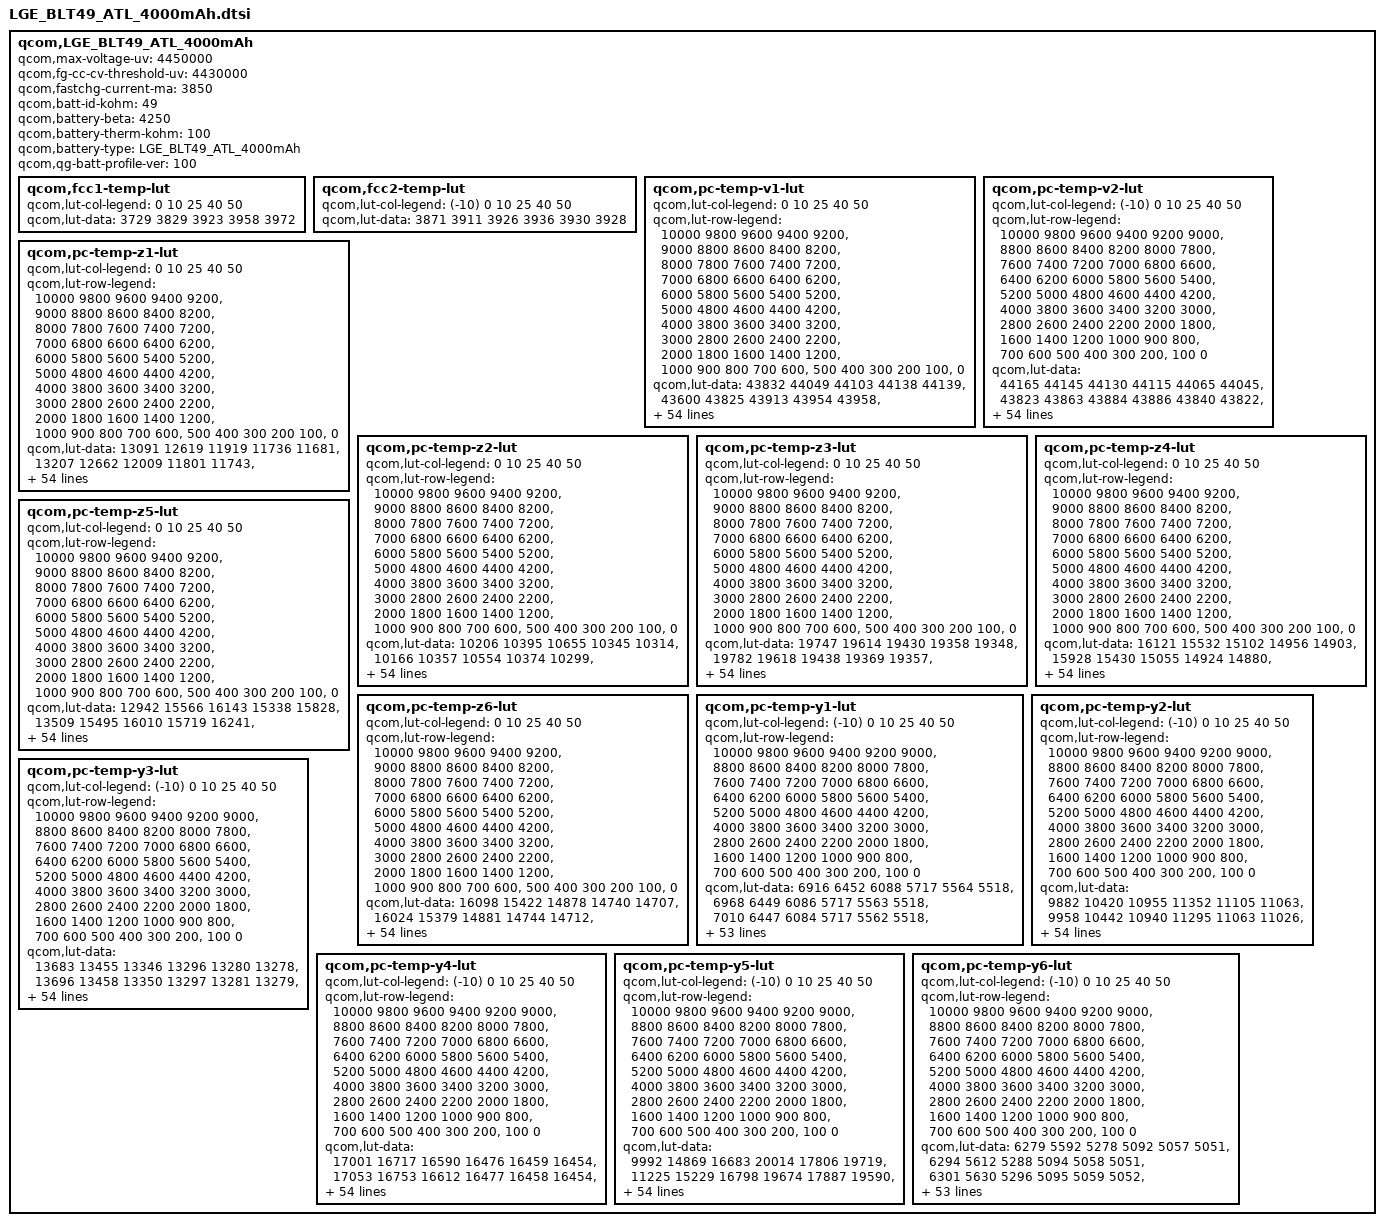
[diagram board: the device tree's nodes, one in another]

qcom,LGE_BLT49_ATL_4000mAh {
    /* 4555251_LGE_BLT49atl_4000mAh_averaged_MasterSlave_May26th2020 */
    qcom,max-voltage-uv = <4450000>;
    qcom,fg-cc-cv-threshold-uv = <4430000>;
    qcom,fastchg-current-ma = <3850>;
    qcom,batt-id-kohm = <49>;
    qcom,battery-beta = <4250>;
    qcom,battery-therm-kohm = <100>;
    qcom,battery-type = "LGE_BLT49_ATL_4000mAh";
    qcom,qg-batt-profile-ver = <100>;

	qcom,fcc1-temp-lut {
		qcom,lut-col-legend = <0 10 25 40 50>;
		qcom,lut-data = <3729 3829 3923 3958 3972>;
	};

	qcom,fcc2-temp-lut {
		qcom,lut-col-legend = <(-10) 0 10 25 40 50>;
		qcom,lut-data = <3871 3911 3926 3936 3930 3928>;
	};

	qcom,pc-temp-v1-lut {
		qcom,lut-col-legend = <0 10 25 40 50>;
		qcom,lut-row-legend = <10000 9800 9600 9400 9200>,
			<9000 8800 8600 8400 8200>,
			<8000 7800 7600 7400 7200>,
			<7000 6800 6600 6400 6200>,
			<6000 5800 5600 5400 5200>,
			<5000 4800 4600 4400 4200>,
			<4000 3800 3600 3400 3200>,
			<3000 2800 2600 2400 2200>,
			<2000 1800 1600 1400 1200>,
			<1000 900 800 700 600>,
			<500 400 300 200 100>,
			<0>;
		qcom,lut-data = <43832 44049 44103 44138 44139>,
			<43600 43825 43913 43954 43958>,
			<43369 43598 43713 43760 43767>,
			<43137 43370 43505 43556 43567>,
			<42905 43139 43287 43343 43357>,
			<42671 42906 43060 43121 43138>,
			<42437 42672 42824 42887 42907>,
			<42205 42433 42585 42648 42671>,
			<41981 42195 42342 42410 42434>,
			<41762 41963 42100 42169 42194>,
			<41546 41735 41864 41933 41957>,
			<41330 41512 41632 41698 41722>,
			<41118 41294 41406 41468 41492>,
			<40917 41083 41186 41242 41265>,
			<40724 40877 40973 41021 41044>,
			<40533 40678 40767 40811 40831>,
			<40338 40486 40567 40609 40626>,
			<40143 40306 40376 40416 40429>,
			<39966 40133 40205 40237 40248>,
			<39818 39955 40031 40065 40076>,
			<39677 39773 39809 39865 39883>,
			<39516 39580 39527 39603 39633>,
			<39333 39353 39287 39351 39383>,
			<39150 39082 39122 39174 39199>,
			<38974 38883 38987 39031 39049>,
			<38803 38785 38867 38901 38914>,
			<38677 38715 38761 38779 38790>,
			<38592 38641 38661 38668 38677>,
			<38525 38565 38563 38568 38573>,
			<38470 38493 38468 38476 38477>,
			<38425 38425 38385 38391 38389>,
			<38385 38360 38310 38312 38306>,
			<38345 38304 38244 38239 38230>,
			<38308 38252 38188 38174 38161>,
			<38271 38206 38139 38115 38098>,
			<38238 38168 38092 38056 38033>,
			<38202 38137 38047 37997 37965>,
			<38155 38098 37999 37934 37891>,
			<38086 38031 37932 37857 37806>,
			<38000 37939 37845 37767 37709>,
			<37897 37836 37746 37667 37603>,
			<37769 37715 37631 37555 37487>,
			<37620 37576 37498 37427 37354>,
			<37456 37409 37335 37262 37189>,
			<37332 37257 37183 37123 37056>,
			<37225 37147 37089 37035 36975>,
			<37187 37115 37064 37011 36953>,
			<37155 37097 37049 36996 36936>,
			<37124 37073 37027 36976 36917>,
			<37073 37034 36989 36932 36863>,
			<36903 36874 36790 36699 36610>,
			<36472 36440 36355 36263 36174>,
			<35897 35860 35790 35696 35606>,
			<35110 35061 35020 34928 34837>,
			<33799 33732 33820 33739 33645>,
			<30000 30000 30000 30000 30000>;
	};

	qcom,pc-temp-v2-lut {
		qcom,lut-col-legend = <(-10) 0 10 25 40 50>;
		qcom,lut-row-legend = <10000 9800 9600 9400 9200 9000>,
			<8800 8600 8400 8200 8000 7800>,
			<7600 7400 7200 7000 6800 6600>,
			<6400 6200 6000 5800 5600 5400>,
			<5200 5000 4800 4600 4400 4200>,
			<4000 3800 3600 3400 3200 3000>,
			<2800 2600 2400 2200 2000 1800>,
			<1600 1400 1200 1000 900 800>,
			<700 600 500 400 300 200>,
			<100 0>;
		qcom,lut-data = <44165 44145 44130 44115 44065 44045>,
			<43823 43863 43884 43886 43840 43822>,
			<43512 43596 43645 43658 43615 43600>,
			<43235 43345 43412 43432 43392 43379>,
			<42993 43113 43189 43210 43171 43160>,
			<42758 42881 42963 42983 42947 42937>,
			<42507 42637 42726 42746 42713 42704>,
			<42250 42390 42483 42504 42473 42466>,
			<41999 42144 42241 42262 42235 42229>,
			<41744 41902 41996 42022 41996 41991>,
			<41507 41661 41756 41784 41760 41757>,
			<41319 41413 41522 41550 41528 41526>,
			<41160 41165 41294 41321 41301 41299>,
			<40963 40961 41075 41097 41079 41077>,
			<40634 40821 40866 40881 40862 40860>,
			<40254 40679 40663 40671 40654 40651>,
			<39965 40456 40468 40467 40453 40451>,
			<39730 40143 40279 40269 40259 40259>,
			<39513 39854 40069 40081 40072 40074>,
			<39303 39619 39810 39910 39901 39903>,
			<39103 39403 39544 39732 39724 39728>,
			<38913 39194 39317 39500 39498 39506>,
			<38724 38995 39111 39216 39223 39235>,
			<38562 38808 38930 38987 38998 39011>,
			<38444 38631 38774 38828 38844 38856>,
			<38350 38469 38636 38697 38716 38728>,
			<38269 38331 38509 38576 38597 38608>,
			<38200 38207 38394 38466 38488 38499>,
			<38138 38109 38287 38366 38390 38399>,
			<38078 38046 38183 38273 38298 38306>,
			<38021 37997 38087 38188 38215 38221>,
			<37964 37951 38002 38110 38140 38143>,
			<37907 37908 37926 38038 38072 38073>,
			<37849 37866 37863 37970 38004 38001>,
			<37789 37822 37821 37906 37927 37917>,
			<37727 37776 37786 37844 37846 37824>,
			<37660 37725 37745 37773 37756 37724>,
			<37590 37666 37699 37690 37652 37608>,
			<37514 37598 37643 37604 37549 37497>,
			<37433 37516 37568 37520 37458 37406>,
			<37341 37417 37470 37435 37371 37324>,
			<37246 37304 37356 37334 37271 37226>,
			<37156 37163 37212 37210 37147 37097>,
			<37070 37018 37059 37078 37023 36968>,
			<36990 36882 36897 36942 36900 36847>,
			<36907 36791 36810 36890 36858 36807>,
			<36858 36759 36784 36874 36847 36796>,
			<36804 36727 36759 36859 36834 36784>,
			<36744 36693 36717 36836 36810 36760>,
			<36676 36625 36641 36779 36741 36675>,
			<36563 36434 36415 36563 36488 36391>,
			<36331 35987 35940 36098 36005 35901>,
			<35882 35311 35285 35481 35384 35273>,
			<35164 34297 34367 34649 34540 34414>,
			<34070 32789 32919 33449 33338 33190>,
			<32413 29665 29552 29551 29565 29552>;
	};

	qcom,pc-temp-z1-lut {
		qcom,lut-col-legend = <0 10 25 40 50>;
		qcom,lut-row-legend = <10000 9800 9600 9400 9200>,
			<9000 8800 8600 8400 8200>,
			<8000 7800 7600 7400 7200>,
			<7000 6800 6600 6400 6200>,
			<6000 5800 5600 5400 5200>,
			<5000 4800 4600 4400 4200>,
			<4000 3800 3600 3400 3200>,
			<3000 2800 2600 2400 2200>,
			<2000 1800 1600 1400 1200>,
			<1000 900 800 700 600>,
			<500 400 300 200 100>,
			<0>;
		qcom,lut-data = <13091 12619 11919 11736 11681>,
			<13207 12662 12009 11801 11743>,
			<13339 12711 12099 11865 11804>,
			<13458 12760 12176 11923 11860>,
			<13538 12805 12227 11969 11906>,
			<13562 12840 12254 11999 11938>,
			<13570 12861 12272 12020 11961>,
			<13577 12873 12283 12036 11978>,
			<13583 12881 12289 12051 11995>,
			<13586 12891 12293 12063 12009>,
			<13590 12902 12300 12067 12014>,
			<13596 12907 12308 12069 12016>,
			<13600 12907 12312 12070 12017>,
			<13599 12906 12312 12071 12019>,
			<13589 12904 12313 12072 12021>,
			<13582 12899 12314 12074 12024>,
			<13592 12895 12316 12077 12026>,
			<13617 12896 12319 12081 12029>,
			<13629 12898 12323 12084 12032>,
			<13619 12900 12327 12087 12035>,
			<13607 12908 12331 12090 12038>,
			<13606 12916 12334 12091 12041>,
			<13618 12919 12339 12093 12043>,
			<13629 12922 12344 12097 12047>,
			<13628 12925 12351 12103 12052>,
			<13619 12932 12357 12108 12056>,
			<13615 12940 12363 12112 12061>,
			<13619 12943 12369 12116 12065>,
			<13625 12942 12373 12121 12069>,
			<13626 12941 12376 12125 12073>,
			<13624 12944 12381 12130 12076>,
			<13624 12951 12390 12133 12079>,
			<13627 12957 12398 12136 12082>,
			<13632 12963 12402 12140 12086>,
			<13637 12968 12404 12145 12089>,
			<13641 12970 12408 12150 12093>,
			<13645 12972 12413 12154 12096>,
			<13653 12975 12419 12158 12100>,
			<13672 12984 12425 12161 12103>,
			<13692 13002 12432 12164 12105>,
			<13700 13015 12438 12168 12108>,
			<13706 13026 12442 12172 12112>,
			<13718 13030 12447 12175 12115>,
			<13734 13034 12462 12180 12118>,
			<13715 13038 12470 12186 12123>,
			<13734 13052 12481 12189 12125>,
			<13745 13045 12474 12190 12126>,
			<13744 13055 12480 12190 12126>,
			<13746 13053 12477 12191 12128>,
			<13754 13052 12484 12194 12130>,
			<13749 13071 12487 12199 12135>,
			<13795 13104 12505 12211 12144>,
			<13831 13133 12529 12224 12159>,
			<13846 13154 12558 12248 12179>,
			<13846 13154 12558 12248 12179>,
			<13846 13154 12558 12248 12179>;
	};

	qcom,pc-temp-z2-lut {
		qcom,lut-col-legend = <0 10 25 40 50>;
		qcom,lut-row-legend = <10000 9800 9600 9400 9200>,
			<9000 8800 8600 8400 8200>,
			<8000 7800 7600 7400 7200>,
			<7000 6800 6600 6400 6200>,
			<6000 5800 5600 5400 5200>,
			<5000 4800 4600 4400 4200>,
			<4000 3800 3600 3400 3200>,
			<3000 2800 2600 2400 2200>,
			<2000 1800 1600 1400 1200>,
			<1000 900 800 700 600>,
			<500 400 300 200 100>,
			<0>;
		qcom,lut-data = <10206 10395 10655 10345 10314>,
			<10166 10357 10554 10374 10299>,
			<10128 10316 10493 10396 10278>,
			<10094 10276 10460 10409 10254>,
			<10065 10239 10443 10409 10232>,
			<10041 10208 10490 10393 10212>,
			<10017 10188 10618 10365 10187>,
			<10004 10173 10647 10332 10167>,
			<10019 10163 10495 10288 10158>,
			<10056 10155 10347 10239 10148>,
			<10071 10149 10403 10220 10142>,
			<10041 10147 10591 10220 10139>,
			<10004 10156 10677 10226 10138>,
			<9999 10174 10671 10235 10143>,
			<10008 10192 10661 10252 10152>,
			<10020 10214 10672 10258 10162>,
			<10029 10238 10708 10260 10178>,
			<10037 10265 10727 10266 10199>,
			<10050 10292 10619 10279 10222>,
			<10088 10303 10473 10299 10250>,
			<10130 10302 10465 10338 10287>,
			<10142 10301 10507 10466 10380>,
			<10145 10298 10531 10577 10467>,
			<10147 10293 10481 10544 10470>,
			<10148 10290 10404 10443 10448>,
			<10148 10289 10397 10408 10426>,
			<10149 10288 10457 10480 10411>,
			<10155 10289 10501 10552 10394>,
			<10164 10299 10486 10518 10343>,
			<10173 10309 10458 10398 10231>,
			<10182 10314 10446 10321 10172>,
			<10190 10318 10443 10288 10168>,
			<10200 10323 10442 10270 10171>,
			<10209 10332 10446 10273 10186>,
			<10218 10343 10457 10295 10231>,
			<10226 10350 10469 10324 10281>,
			<10235 10355 10490 10384 10332>,
			<10246 10361 10517 10455 10383>,
			<10263 10376 10546 10507 10430>,
			<10283 10395 10578 10553 10476>,
			<10302 10409 10598 10571 10497>,
			<10324 10417 10608 10537 10488>,
			<10362 10429 10615 10509 10474>,
			<10408 10457 10620 10537 10455>,
			<10390 10639 10675 10527 10452>,
			<10586 10700 10695 10534 10427>,
			<10759 10699 10681 10535 10451>,
			<11152 10873 10684 10554 10471>,
			<11134 11184 10646 10552 10484>,
			<12225 11295 10703 10615 10586>,
			<13734 11161 10873 10590 10408>,
			<10485 11109 10830 10375 10236>,
			<10346 10946 10788 10308 10167>,
			<9840 10704 10800 10270 10120>,
			<9840 10704 10800 10270 10120>,
			<9840 10704 10800 10270 10120>;
	};

	qcom,pc-temp-z3-lut {
		qcom,lut-col-legend = <0 10 25 40 50>;
		qcom,lut-row-legend = <10000 9800 9600 9400 9200>,
			<9000 8800 8600 8400 8200>,
			<8000 7800 7600 7400 7200>,
			<7000 6800 6600 6400 6200>,
			<6000 5800 5600 5400 5200>,
			<5000 4800 4600 4400 4200>,
			<4000 3800 3600 3400 3200>,
			<3000 2800 2600 2400 2200>,
			<2000 1800 1600 1400 1200>,
			<1000 900 800 700 600>,
			<500 400 300 200 100>,
			<0>;
		qcom,lut-data = <19747 19614 19430 19358 19348>,
			<19782 19618 19438 19369 19357>,
			<19821 19625 19448 19382 19367>,
			<19857 19633 19459 19394 19377>,
			<19881 19641 19468 19404 19385>,
			<19889 19647 19480 19410 19390>,
			<19892 19650 19493 19415 19395>,
			<19894 19651 19496 19417 19398>,
			<19898 19652 19484 19416 19397>,
			<19902 19651 19472 19412 19395>,
			<19901 19647 19474 19407 19392>,
			<19888 19641 19484 19399 19387>,
			<19871 19634 19486 19393 19383>,
			<19863 19626 19476 19390 19380>,
			<19855 19619 19463 19388 19378>,
			<19851 19613 19457 19385 19375>,
			<19852 19607 19453 19378 19371>,
			<19855 19596 19449 19371 19365>,
			<19856 19583 19437 19367 19360>,
			<19836 19579 19425 19365 19355>,
			<19809 19589 19429 19365 19353>,
			<19806 19602 19455 19379 19361>,
			<19822 19608 19472 19392 19370>,
			<19836 19613 19454 19382 19366>,
			<19835 19615 19425 19354 19350>,
			<19832 19608 19418 19346 19343>,
			<19829 19595 19418 19381 19372>,
			<19823 19591 19421 19417 19405>,
			<19817 19590 19435 19418 19407>,
			<19810 19590 19455 19410 19398>,
			<19801 19592 19461 19403 19389>,
			<19792 19598 19459 19396 19382>,
			<19784 19601 19456 19388 19376>,
			<19776 19598 19451 19382 19368>,
			<19769 19594 19444 19376 19360>,
			<19761 19590 19439 19371 19353>,
			<19754 19584 19437 19369 19350>,
			<19746 19577 19435 19367 19347>,
			<19739 19572 19431 19365 19346>,
			<19730 19568 19427 19364 19346>,
			<19718 19562 19422 19363 19346>,
			<19700 19556 19418 19362 19349>,
			<19680 19547 19414 19361 19353>,
			<19650 19533 19408 19361 19356>,
			<19275 19482 19400 19356 19353>,
			<19260 19464 19390 19349 19346>,
			<19260 19461 19386 19347 19335>,
			<19259 19404 19373 19339 19331>,
			<19259 19330 19373 19337 19327>,
			<19259 19320 19360 19332 19323>,
			<19258 19332 19346 19341 19341>,
			<19260 19325 19351 19358 19353>,
			<19261 19323 19347 19365 19356>,
			<19272 19331 19337 19360 19357>,
			<19272 19331 19337 19360 19357>,
			<19272 19331 19337 19360 19357>;
	};

	qcom,pc-temp-z4-lut {
		qcom,lut-col-legend = <0 10 25 40 50>;
		qcom,lut-row-legend = <10000 9800 9600 9400 9200>,
			<9000 8800 8600 8400 8200>,
			<8000 7800 7600 7400 7200>,
			<7000 6800 6600 6400 6200>,
			<6000 5800 5600 5400 5200>,
			<5000 4800 4600 4400 4200>,
			<4000 3800 3600 3400 3200>,
			<3000 2800 2600 2400 2200>,
			<2000 1800 1600 1400 1200>,
			<1000 900 800 700 600>,
			<500 400 300 200 100>,
			<0>;
		qcom,lut-data = <16121 15532 15102 14956 14903>,
			<15928 15430 15055 14924 14880>,
			<15746 15330 15009 14895 14859>,
			<15583 15234 14962 14867 14838>,
			<15446 15146 14917 14842 14819>,
			<15341 15071 14868 14819 14800>,
			<15258 15010 14819 14797 14782>,
			<15184 14961 14796 14779 14765>,
			<15102 14920 14786 14761 14748>,
			<15023 14887 14777 14746 14731>,
			<14980 14859 14756 14736 14721>,
			<14963 14835 14717 14729 14715>,
			<14948 14813 14700 14723 14711>,
			<14931 14795 14700 14715 14705>,
			<14903 14783 14701 14706 14697>,
			<14877 14773 14698 14701 14692>,
			<14862 14767 14693 14698 14687>,
			<14851 14767 14689 14695 14683>,
			<14838 14768 14691 14690 14678>,
			<14819 14769 14700 14683 14672>,
			<14802 14767 14721 14684 14672>,
			<14799 14766 14770 14728 14716>,
			<14805 14789 14814 14784 14772>,
			<14815 14874 14844 14817 14795>,
			<14842 14927 14866 14843 14810>,
			<14892 14915 14867 14849 14815>,
			<14915 14891 14847 14798 14772>,
			<14911 14869 14821 14739 14717>,
			<14902 14850 14789 14722 14703>,
			<14891 14832 14754 14714 14698>,
			<14874 14815 14737 14707 14694>,
			<14857 14800 14729 14701 14688>,
			<14842 14790 14724 14697 14683>,
			<14828 14784 14722 14694 14681>,
			<14815 14780 14721 14692 14679>,
			<14802 14775 14721 14692 14679>,
			<14790 14768 14721 14695 14683>,
			<14780 14763 14722 14700 14690>,
			<14772 14760 14725 14707 14697>,
			<14765 14759 14731 14717 14707>,
			<14758 14754 14733 14721 14711>,
			<14753 14740 14722 14712 14701>,
			<14744 14727 14710 14705 14693>,
			<14735 14719 14706 14706 14696>,
			<15007 14700 14685 14694 14685>,
			<15014 14686 14674 14681 14672>,
			<15011 14686 14666 14673 14671>,
			<15008 14733 14664 14661 14657>,
			<15001 14810 14651 14645 14640>,
			<14992 14818 14659 14642 14634>,
			<14992 14807 14691 14662 14654>,
			<15016 14830 14699 14659 14653>,
			<15028 14839 14707 14654 14654>,
			<15045 14841 14720 14660 14652>,
			<15045 14841 14720 14660 14652>,
			<15045 14841 14720 14660 14652>;
	};

	qcom,pc-temp-z5-lut {
		qcom,lut-col-legend = <0 10 25 40 50>;
		qcom,lut-row-legend = <10000 9800 9600 9400 9200>,
			<9000 8800 8600 8400 8200>,
			<8000 7800 7600 7400 7200>,
			<7000 6800 6600 6400 6200>,
			<6000 5800 5600 5400 5200>,
			<5000 4800 4600 4400 4200>,
			<4000 3800 3600 3400 3200>,
			<3000 2800 2600 2400 2200>,
			<2000 1800 1600 1400 1200>,
			<1000 900 800 700 600>,
			<500 400 300 200 100>,
			<0>;
		qcom,lut-data = <12942 15566 16143 15338 15828>,
			<13509 15495 16010 15719 16241>,
			<14044 15580 16134 16246 16742>,
			<14542 15798 16439 16825 17283>,
			<14995 16128 16850 17362 17818>,
			<15387 16546 17573 17797 18306>,
			<15714 17034 18596 18288 18805>,
			<16078 17647 19016 18697 19311>,
			<16639 18328 18809 18976 19894>,
			<17329 18997 18637 19198 20549>,
			<17815 19678 20423 19260 20868>,
			<18120 20412 24985 19107 20852>,
			<18430 21222 26883 19088 20855>,
			<18872 22118 25689 19666 21328>,
			<19648 23194 24342 20552 22268>,
			<20684 24705 24414 20772 22835>,
			<22380 25680 25189 20336 23238>,
			<24721 25105 25752 19947 23518>,
			<26016 23664 24416 20179 23592>,
			<26219 23360 22638 21022 23883>,
			<26370 29294 25606 22467 24334>,
			<28537 36325 37732 26890 26017>,
			<38974 37792 45089 30688 27697>,
			<47572 37779 36510 27424 25614>,
			<47641 37118 22798 18451 18393>,
			<46554 33343 18819 15153 15031>,
			<45178 27863 17931 17960 17991>,
			<42742 26226 17576 21138 21756>,
			<39750 26047 19196 21844 22683>,
			<37655 25985 22826 22087 22975>,
			<35916 27104 25698 22417 23352>,
			<34702 30283 28187 23026 24348>,
			<34189 33016 29985 23740 25328>,
			<33840 35285 30730 24418 25372>,
			<33717 36965 31212 25123 25019>,
			<33962 37089 31737 25663 24817>,
			<34467 36575 32460 26094 24621>,
			<35099 36169 32968 26381 24244>,
			<36419 36104 32183 26021 23550>,
			<37490 36087 29693 24427 22070>,
			<36516 35888 27996 23080 21299>,
			<33405 34923 27407 22344 21915>,
			<31701 33684 26712 21889 22744>,
			<30328 31228 25123 21759 23505>,
			<12230 28120 27181 21853 23689>,
			<11514 26694 26106 20751 21722>,
			<11472 25776 25518 20991 18835>,
			<11432 16343 21508 20376 19836>,
			<11415 12778 23026 23304 22865>,
			<11432 12524 19658 22642 24524>,
			<11459 12907 16163 19599 21881>,
			<11422 12559 15637 20537 21687>,
			<11340 12386 14872 21464 20779>,
			<11571 12783 13935 18520 19685>,
			<11571 12783 13935 18520 19685>,
			<11571 12783 13935 18520 19685>;
	};

	qcom,pc-temp-z6-lut {
		qcom,lut-col-legend = <0 10 25 40 50>;
		qcom,lut-row-legend = <10000 9800 9600 9400 9200>,
			<9000 8800 8600 8400 8200>,
			<8000 7800 7600 7400 7200>,
			<7000 6800 6600 6400 6200>,
			<6000 5800 5600 5400 5200>,
			<5000 4800 4600 4400 4200>,
			<4000 3800 3600 3400 3200>,
			<3000 2800 2600 2400 2200>,
			<2000 1800 1600 1400 1200>,
			<1000 900 800 700 600>,
			<500 400 300 200 100>,
			<0>;
		qcom,lut-data = <16098 15422 14878 14740 14707>,
			<16024 15379 14881 14744 14712>,
			<15953 15337 14880 14750 14718>,
			<15889 15297 14877 14755 14724>,
			<15831 15260 14872 14758 14729>,
			<15781 15227 14864 14756 14729>,
			<15739 15198 14853 14754 14728>,
			<15699 15174 14843 14750 14726>,
			<15656 15152 14834 14745 14722>,
			<15614 15133 14825 14739 14716>,
			<15584 15115 14816 14732 14710>,
			<15565 15099 14808 14725 14706>,
			<15550 15084 14800 14719 14701>,
			<15530 15070 14794 14714 14697>,
			<15505 15059 14789 14709 14693>,
			<15486 15050 14784 14705 14689>,
			<15478 15044 14780 14700 14685>,
			<15473 15038 14777 14696 14680>,
			<15465 15032 14773 14692 14676>,
			<15444 15031 14771 14688 14671>,
			<15422 15035 14780 14689 14670>,
			<15419 15043 14819 14719 14695>,
			<15430 15061 14845 14749 14724>,
			<15444 15102 14846 14752 14729>,
			<15461 15126 14846 14753 14730>,
			<15481 15118 14843 14753 14730>,
			<15489 15104 14836 14750 14728>,
			<15487 15093 14828 14745 14723>,
			<15483 15084 14823 14740 14718>,
			<15477 15078 14819 14733 14712>,
			<15467 15076 14815 14727 14706>,
			<15457 15074 14813 14721 14701>,
			<15449 15073 14810 14716 14696>,
			<15441 15070 14807 14711 14690>,
			<15434 15068 14803 14707 14685>,
			<15426 15064 14802 14705 14682>,
			<15419 15059 14801 14706 14683>,
			<15418 15056 14802 14707 14683>,
			<15421 15058 14802 14709 14685>,
			<15425 15061 14803 14713 14689>,
			<15424 15061 14804 14714 14692>,
			<15420 15057 14798 14710 14690>,
			<15415 15052 14792 14707 14689>,
			<15406 15049 14790 14708 14692>,
			<15343 15025 14780 14701 14686>,
			<15349 15010 14772 14693 14678>,
			<15351 15013 14766 14689 14672>,
			<15351 15006 14758 14679 14663>,
			<15352 15004 14754 14671 14654>,
			<15351 15005 14752 14667 14649>,
			<15355 15014 14760 14682 14669>,
			<15389 15028 14771 14692 14678>,
			<15412 15042 14778 14697 14683>,
			<15449 15063 14785 14702 14687>,
			<15449 15063 14785 14702 14687>,
			<15449 15063 14785 14702 14687>;
	};

	qcom,pc-temp-y1-lut {
		qcom,lut-col-legend = <(-10) 0 10 25 40 50>;
		qcom,lut-row-legend = <10000 9800 9600 9400 9200 9000>,
			<8800 8600 8400 8200 8000 7800>,
			<7600 7400 7200 7000 6800 6600>,
			<6400 6200 6000 5800 5600 5400>,
			<5200 5000 4800 4600 4400 4200>,
			<4000 3800 3600 3400 3200 3000>,
			<2800 2600 2400 2200 2000 1800>,
			<1600 1400 1200 1000 900 800>,
			<700 600 500 400 300 200>,
			<100 0>;
		qcom,lut-data = <6916 6452 6088 5717 5564 5518>,
			<6968 6449 6086 5717 5563 5518>,
			<7010 6447 6084 5717 5562 5518>,
			<7041 6447 6081 5716 5560 5518>,
			<7062 6447 6078 5715 5558 5518>,
			<7070 6447 6076 5713 5557 5519>,
			<7062 6452 6075 5712 5556 5520>,
			<7044 6459 6073 5710 5556 5521>,
			<7033 6462 6074 5707 5556 5521>,
			<7036 6466 6083 5704 5556 5521>,
			<7041 6470 6092 5701 5556 5521>,
			<7043 6470 6088 5702 5556 5521>,
			<7048 6468 6077 5703 5557 5523>,
			<7051 6468 6073 5704 5559 5525>,
			<7048 6474 6072 5705 5559 5526>,
			<7043 6480 6071 5705 5560 5527>,
			<7043 6482 6075 5706 5562 5528>,
			<7049 6482 6085 5707 5563 5530>,
			<7054 6481 6090 5708 5565 5531>,
			<7060 6480 6088 5712 5567 5533>,
			<7069 6480 6085 5716 5568 5534>,
			<7071 6480 6085 5718 5570 5536>,
			<7064 6483 6088 5721 5573 5537>,
			<7058 6486 6090 5724 5575 5539>,
			<7061 6493 6096 5729 5577 5541>,
			<7070 6501 6105 5733 5580 5543>,
			<7074 6502 6108 5737 5582 5545>,
			<7069 6497 6117 5740 5584 5547>,
			<7063 6493 6121 5743 5586 5549>,
			<7066 6493 6115 5746 5588 5551>,
			<7079 6493 6106 5749 5592 5552>,
			<7087 6495 6105 5754 5595 5555>,
			<7085 6507 6111 5760 5598 5558>,
			<7082 6518 6116 5766 5600 5562>,
			<7080 6517 6120 5770 5603 5563>,
			<7084 6512 6124 5773 5605 5565>,
			<7089 6512 6126 5776 5608 5567>,
			<7095 6519 6129 5779 5609 5569>,
			<7104 6528 6132 5782 5611 5571>,
			<7107 6536 6139 5785 5613 5573>,
			<7106 6547 6149 5788 5615 5574>,
			<7105 6553 6155 5790 5617 5575>,
			<7119 6565 6158 5791 5619 5577>,
			<7154 6574 6159 5795 5621 5579>,
			<7168 6590 6159 5808 5624 5583>,
			<7188 6605 6165 5815 5627 5584>,
			<7250 6616 6176 5813 5627 5585>,
			<7306 6629 6189 5813 5628 5585>,
			<7288 6647 6183 5812 5628 5585>,
			<7348 6681 6185 5811 5628 5586>,
			<7454 6743 6199 5816 5631 5588>,
			<7691 6860 6245 5830 5637 5595>,
			<8203 7188 6345 5846 5648 5605>,
			<10858 9431 6569 5867 5661 5617>,
			<10858 9431 6569 5867 5661 5617>,
			<10858 9431 6569 5867 5661 5617>;
	};

	qcom,pc-temp-y2-lut {
		qcom,lut-col-legend = <(-10) 0 10 25 40 50>;
		qcom,lut-row-legend = <10000 9800 9600 9400 9200 9000>,
			<8800 8600 8400 8200 8000 7800>,
			<7600 7400 7200 7000 6800 6600>,
			<6400 6200 6000 5800 5600 5400>,
			<5200 5000 4800 4600 4400 4200>,
			<4000 3800 3600 3400 3200 3000>,
			<2800 2600 2400 2200 2000 1800>,
			<1600 1400 1200 1000 900 800>,
			<700 600 500 400 300 200>,
			<100 0>;
		qcom,lut-data = <9882 10420 10955 11352 11105 11063>,
			<9958 10442 10940 11295 11063 11026>,
			<10035 10473 10925 11236 11021 10984>,
			<10108 10507 10909 11181 10983 10941>,
			<10173 10537 10892 11132 10949 10901>,
			<10226 10553 10875 11096 10920 10869>,
			<10263 10559 10856 11070 10893 10844>,
			<10292 10562 10837 11050 10871 10820>,
			<10338 10561 10824 11033 10869 10800>,
			<10458 10546 10814 11016 10898 10777>,
			<10566 10532 10808 11005 10923 10762>,
			<10507 10585 10813 10998 10913 10764>,
			<10276 10720 10829 10991 10886 10772>,
			<10129 10774 10853 10992 10871 10774>,
			<9955 10753 10899 11008 10879 10770>,
			<9741 10729 10958 11035 10894 10766>,
			<9690 10748 11022 11076 10915 10781>,
			<9682 10824 11094 11142 10962 10836>,
			<9678 10889 11121 11206 11021 10904>,
			<9676 10930 11108 11278 11152 11018>,
			<9674 10960 11094 11331 11273 11118>,
			<9672 10969 11096 11316 11258 11117>,
			<9671 10966 11113 11253 11166 11076>,
			<9670 10957 11128 11222 11119 11054>,
			<9669 10919 11140 11242 11146 11063>,
			<9668 10856 11153 11274 11190 11082>,
			<9667 10772 11168 11298 11219 11108>,
			<9667 10533 11187 11320 11245 11148>,
			<9666 10351 11197 11338 11265 11186>,
			<9666 10321 11182 11351 11281 11247>,
			<9665 10279 11156 11363 11301 11322>,
			<9664 10206 11149 11382 11334 11343>,
			<9664 9947 11148 11409 11418 11325>,
			<9664 9715 11147 11424 11475 11310>,
			<9663 9690 11128 11413 11428 11314>,
			<9663 9683 11084 11392 11338 11320>,
			<9663 9678 11043 11381 11300 11319>,
			<9662 9673 11004 11374 11287 11293>,
			<9662 9669 10958 11365 11278 11257>,
			<9662 9666 10893 11350 11260 11213>,
			<9662 9664 10805 11324 11232 11162>,
			<9661 9662 10682 11297 11219 11140>,
			<9661 9661 10447 11269 11216 11139>,
			<9660 9660 10215 11229 11206 11128>,
			<9659 9659 9923 11161 11131 11044>,
			<9657 9658 9770 11080 10982 10875>,
			<9655 9658 9764 11094 10974 10842>,
			<9654 9657 9774 11116 11008 10844>,
			<9653 9656 9715 11107 11055 10859>,
			<9651 9654 9687 11111 11062 10875>,
			<9649 9652 9672 11109 10991 10857>,
			<9648 9649 9661 11051 10935 10801>,
			<9647 9648 9654 10957 10860 10725>,
			<9647 9648 9650 10858 10778 10585>,
			<9647 9648 9650 10858 10778 10585>,
			<9647 9648 9650 10858 10778 10585>;
	};

	qcom,pc-temp-y3-lut {
		qcom,lut-col-legend = <(-10) 0 10 25 40 50>;
		qcom,lut-row-legend = <10000 9800 9600 9400 9200 9000>,
			<8800 8600 8400 8200 8000 7800>,
			<7600 7400 7200 7000 6800 6600>,
			<6400 6200 6000 5800 5600 5400>,
			<5200 5000 4800 4600 4400 4200>,
			<4000 3800 3600 3400 3200 3000>,
			<2800 2600 2400 2200 2000 1800>,
			<1600 1400 1200 1000 900 800>,
			<700 600 500 400 300 200>,
			<100 0>;
		qcom,lut-data = <13683 13455 13346 13296 13280 13278>,
			<13696 13458 13350 13297 13281 13279>,
			<13701 13464 13353 13298 13282 13280>,
			<13700 13470 13357 13298 13284 13281>,
			<13695 13475 13360 13299 13285 13282>,
			<13688 13477 13363 13300 13286 13283>,
			<13675 13477 13366 13301 13287 13284>,
			<13658 13477 13368 13302 13288 13284>,
			<13643 13476 13369 13303 13289 13285>,
			<13621 13474 13369 13304 13290 13286>,
			<13602 13470 13370 13305 13291 13287>,
			<13594 13459 13369 13306 13292 13288>,
			<13576 13437 13367 13306 13293 13289>,
			<13566 13428 13365 13307 13294 13290>,
			<13568 13433 13360 13310 13295 13290>,
			<13570 13438 13356 13313 13296 13291>,
			<13561 13436 13357 13311 13297 13292>,
			<13541 13430 13363 13306 13298 13295>,
			<13527 13422 13366 13304 13298 13296>,
			<13525 13414 13359 13308 13297 13296>,
			<13525 13404 13349 13313 13296 13295>,
			<13524 13394 13343 13311 13293 13292>,
			<13522 13383 13339 13301 13286 13284>,
			<13520 13376 13336 13296 13282 13280>,
			<13522 13374 13335 13295 13282 13280>,
			<13528 13373 13333 13295 13282 13280>,
			<13537 13369 13331 13294 13282 13280>,
			<13558 13358 13329 13294 13281 13280>,
			<13588 13350 13328 13294 13280 13280>,
			<13619 13351 13327 13294 13280 13280>,
			<13654 13357 13326 13295 13280 13279>,
			<13688 13365 13325 13295 13281 13279>,
			<13718 13382 13323 13295 13282 13279>,
			<13749 13404 13321 13296 13283 13279>,
			<13786 13427 13323 13296 13283 13279>,
			<13832 13453 13327 13296 13283 13279>,
			<13877 13483 13330 13295 13282 13279>,
			<13920 13521 13333 13294 13282 13278>,
			<13960 13567 13336 13293 13281 13277>,
			<13993 13622 13339 13293 13281 13278>,
			<14017 13689 13343 13293 13281 13281>,
			<14041 13756 13346 13294 13281 13282>,
			<14079 13818 13350 13295 13282 13281>,
			<14135 13883 13355 13295 13282 13280>,
			<14227 13956 13367 13295 13281 13279>,
			<14407 14059 13396 13298 13285 13283>,
			<14637 14098 13400 13299 13289 13287>,
			<14854 14091 13401 13301 13292 13289>,
			<14979 14222 13436 13307 13295 13291>,
			<15771 14503 13490 13311 13295 13290>,
			<17341 15130 13562 13307 13290 13286>,
			<21345 16869 13754 13304 13289 13286>,
			<33003 22947 14383 13310 13291 13288>,
			<65535 49130 16359 13318 13296 13293>,
			<65535 49130 16359 13318 13296 13293>,
			<65535 49130 16359 13318 13296 13293>;
	};

	qcom,pc-temp-y4-lut {
		qcom,lut-col-legend = <(-10) 0 10 25 40 50>;
		qcom,lut-row-legend = <10000 9800 9600 9400 9200 9000>,
			<8800 8600 8400 8200 8000 7800>,
			<7600 7400 7200 7000 6800 6600>,
			<6400 6200 6000 5800 5600 5400>,
			<5200 5000 4800 4600 4400 4200>,
			<4000 3800 3600 3400 3200 3000>,
			<2800 2600 2400 2200 2000 1800>,
			<1600 1400 1200 1000 900 800>,
			<700 600 500 400 300 200>,
			<100 0>;
		qcom,lut-data = <17001 16717 16590 16476 16459 16454>,
			<17053 16753 16612 16477 16458 16454>,
			<17114 16816 16639 16479 16458 16454>,
			<17173 16888 16667 16481 16458 16454>,
			<17219 16948 16688 16484 16458 16454>,
			<17241 16976 16697 16485 16458 16454>,
			<17236 16974 16694 16486 16459 16454>,
			<17221 16968 16688 16488 16460 16454>,
			<17211 16967 16686 16489 16461 16455>,
			<17202 16973 16687 16492 16463 16456>,
			<17199 16984 16688 16497 16465 16458>,
			<17236 17002 16695 16503 16469 16461>,
			<17340 17035 16713 16512 16474 16464>,
			<17392 17068 16736 16521 16479 16467>,
			<17285 17119 16780 16528 16484 16473>,
			<17124 17161 16816 16538 16490 16478>,
			<17055 17131 16818 16558 16498 16483>,
			<17025 17005 16815 16590 16510 16488>,
			<16996 16907 16810 16615 16525 16496>,
			<16954 16862 16762 16635 16559 16524>,
			<16908 16827 16695 16648 16590 16553>,
			<16865 16790 16652 16623 16574 16543>,
			<16817 16752 16616 16539 16510 16495>,
			<16787 16712 16593 16492 16473 16466>,
			<16789 16658 16581 16485 16467 16461>,
			<16798 16605 16572 16481 16464 16458>,
			<16804 16589 16566 16482 16465 16459>,
			<16806 16595 16562 16485 16471 16462>,
			<16806 16606 16558 16489 16478 16467>,
			<16804 16615 16545 16494 16485 16474>,
			<16801 16628 16530 16500 16494 16482>,
			<16799 16644 16524 16507 16504 16492>,
			<16801 16665 16519 16514 16514 16505>,
			<16804 16686 16516 16520 16520 16512>,
			<16806 16702 16524 16522 16518 16510>,
			<16811 16716 16542 16523 16513 16504>,
			<16814 16728 16561 16520 16506 16496>,
			<16812 16739 16583 16501 16486 16482>,
			<16807 16746 16602 16486 16470 16472>,
			<16805 16746 16614 16484 16470 16472>,
			<16803 16743 16623 16484 16471 16474>,
			<16802 16738 16629 16484 16471 16474>,
			<16808 16720 16634 16488 16469 16470>,
			<16828 16704 16636 16488 16465 16461>,
			<16852 16696 16636 16482 16452 16445>,
			<16893 16703 16653 16494 16460 16457>,
			<16976 16711 16654 16497 16471 16474>,
			<17029 16709 16649 16502 16491 16502>,
			<17016 16729 16682 16524 16524 16534>,
			<17210 16807 16713 16549 16535 16536>,
			<17572 16948 16725 16526 16493 16479>,
			<18395 17245 16718 16498 16460 16458>,
			<21451 19029 16835 16506 16464 16461>,
			<45291 39637 17836 16537 16480 16474>,
			<45291 39637 17836 16537 16480 16474>,
			<45291 39637 17836 16537 16480 16474>;
	};

	qcom,pc-temp-y5-lut {
		qcom,lut-col-legend = <(-10) 0 10 25 40 50>;
		qcom,lut-row-legend = <10000 9800 9600 9400 9200 9000>,
			<8800 8600 8400 8200 8000 7800>,
			<7600 7400 7200 7000 6800 6600>,
			<6400 6200 6000 5800 5600 5400>,
			<5200 5000 4800 4600 4400 4200>,
			<4000 3800 3600 3400 3200 3000>,
			<2800 2600 2400 2200 2000 1800>,
			<1600 1400 1200 1000 900 800>,
			<700 600 500 400 300 200>,
			<100 0>;
		qcom,lut-data = <9992 14869 16683 20014 17806 19719>,
			<11225 15229 16798 19674 17887 19590>,
			<12778 15584 16935 19031 17920 19376>,
			<14378 15916 17072 18268 17916 19130>,
			<15752 16206 17188 17568 17886 18900>,
			<16622 16436 17263 17114 17842 18737>,
			<16982 16628 17308 16852 17776 18633>,
			<17216 16783 17339 16578 17673 18524>,
			<17375 16805 17291 16361 17528 18404>,
			<17694 16595 16871 16124 17277 18161>,
			<17990 16244 16334 15829 16955 17856>,
			<18042 15568 15901 15343 16536 17535>,
			<18072 14512 15485 14752 16029 17149>,
			<18065 14225 15198 14576 15698 16709>,
			<17658 16509 14940 14614 15535 16060>,
			<17078 19203 14772 14650 15475 15578>,
			<16670 19871 16024 14391 15262 15640>,
			<15478 20115 19679 13704 14664 15908>,
			<14636 20429 21466 13587 14447 16021>,
			<14673 21083 21649 16990 14819 15845>,
			<14757 21776 21731 20705 15432 15642>,
			<14709 22086 21769 20840 16184 16011>,
			<13950 22222 21909 20129 17201 17437>,
			<13079 22423 22065 19742 17776 18285>,
			<12616 23355 22317 19706 17952 18405>,
			<12218 24590 22622 19677 18034 18473>,
			<12058 24003 22776 19595 17745 18322>,
			<12094 18327 22788 19432 16613 17510>,
			<12184 13741 22875 19349 15920 16818>,
			<12313 13361 23391 19522 15920 16359>,
			<12575 13209 24046 19874 15959 15901>,
			<12808 13182 23764 20252 16153 15816>,
			<12992 13229 21123 20723 17018 15845>,
			<13182 13323 19129 21252 17961 15978>,
			<13338 13529 19194 22023 18637 16806>,
			<13523 13900 19369 22808 19238 18128>,
			<13672 14202 19394 22867 19701 18525>,
			<13787 14442 19125 22058 20218 18326>,
			<13922 14608 18787 21057 20538 18159>,
			<13945 14635 18562 20126 20059 19188>,
			<13584 14610 18352 19232 18997 21410>,
			<13077 14568 18077 18951 18688 22177>,
			<12673 14338 17346 18965 19214 21945>,
			<12332 14051 16499 18890 19318 21265>,
			<12368 13661 15161 18563 17996 18088>,
			<12504 13477 14287 17440 17087 17713>,
			<12203 13493 14282 17170 17556 17622>,
			<11874 13302 14336 17523 17858 16943>,
			<11726 13637 14025 18311 17367 16222>,
			<11368 13068 14312 18617 16798 15907>,
			<10672 12101 14299 18728 17065 16577>,
			<9843 10766 14018 19475 19078 18285>,
			<9138 9502 12831 20354 19242 18268>,
			<8836 8869 10475 22351 22759 22096>,
			<8836 8869 10475 22351 22759 22096>,
			<8836 8869 10475 22351 22759 22096>;
	};

	qcom,pc-temp-y6-lut {
		qcom,lut-col-legend = <(-10) 0 10 25 40 50>;
		qcom,lut-row-legend = <10000 9800 9600 9400 9200 9000>,
			<8800 8600 8400 8200 8000 7800>,
			<7600 7400 7200 7000 6800 6600>,
			<6400 6200 6000 5800 5600 5400>,
			<5200 5000 4800 4600 4400 4200>,
			<4000 3800 3600 3400 3200 3000>,
			<2800 2600 2400 2200 2000 1800>,
			<1600 1400 1200 1000 900 800>,
			<700 600 500 400 300 200>,
			<100 0>;
		qcom,lut-data = <6279 5592 5278 5092 5057 5051>,
			<6294 5612 5288 5094 5058 5051>,
			<6301 5630 5296 5095 5059 5052>,
			<6302 5646 5301 5096 5060 5053>,
			<6298 5657 5304 5097 5061 5054>,
			<6291 5661 5305 5098 5062 5055>,
			<6277 5658 5304 5099 5063 5056>,
			<6254 5652 5300 5100 5064 5056>,
			<6235 5647 5297 5101 5065 5057>,
			<6216 5645 5295 5102 5066 5059>,
			<6201 5642 5294 5103 5068 5060>,
			<6198 5638 5295 5106 5070 5061>,
			<6201 5633 5297 5109 5071 5063>,
			<6199 5632 5300 5112 5074 5065>,
			<6159 5650 5306 5116 5076 5067>,
			<6102 5670 5313 5120 5079 5069>,
			<6071 5663 5316 5125 5082 5071>,
			<6050 5629 5319 5131 5086 5074>,
			<6035 5600 5319 5137 5091 5079>,
			<6028 5584 5301 5145 5099 5086>,
			<6024 5571 5275 5152 5107 5093>,
			<6019 5560 5259 5143 5101 5088>,
			<6012 5550 5246 5113 5077 5069>,
			<6008 5542 5239 5096 5064 5057>,
			<6012 5536 5236 5095 5062 5056>,
			<6026 5531 5235 5094 5062 5055>,
			<6043 5530 5234 5094 5062 5055>,
			<6065 5534 5235 5095 5063 5056>,
			<6091 5541 5235 5097 5065 5058>,
			<6117 5554 5233 5099 5067 5060>,
			<6144 5578 5231 5101 5070 5063>,
			<6172 5604 5231 5103 5073 5065>,
			<6197 5636 5233 5107 5078 5069>,
			<6223 5673 5235 5110 5080 5071>,
			<6255 5714 5243 5111 5080 5071>,
			<6298 5760 5258 5112 5079 5070>,
			<6341 5809 5274 5112 5076 5068>,
			<6376 5859 5292 5106 5070 5063>,
			<6408 5912 5312 5101 5066 5059>,
			<6437 5973 5335 5101 5066 5060>,
			<6459 6041 5360 5102 5067 5063>,
			<6483 6106 5388 5104 5067 5064>,
			<6522 6160 5419 5106 5067 5062>,
			<6585 6217 5453 5107 5066 5059>,
			<6683 6286 5494 5108 5062 5055>,
			<6873 6388 5561 5116 5068 5062>,
			<7124 6429 5568 5116 5074 5070>,
			<7353 6433 5566 5119 5082 5079>,
			<7471 6556 5630 5130 5093 5090>,
			<8224 6847 5718 5140 5096 5090>,
			<9604 7458 5827 5131 5081 5071>,
			<12873 8955 6053 5123 5072 5065>,
			<21971 13922 6705 5133 5076 5069>,
			<57220 37587 8510 5153 5086 5079>,
			<57220 37587 8510 5153 5086 5079>,
			<57220 37587 8510 5153 5086 5079>;
	};

};
